# STM32G473xx register map
File version: 1.0
Registers are 32-bit, read-write, reset 0x0 unless marked. A register's access mark holds for its fields unless they carry their own. Offsets are from the block's base; [hi:lo] are bit positions; {n}, {i} and the like mark numbered series.

## OPAMP — Operational Amplifier (OPAMP)
Base 0x40010300
Same registers: OPAMP1 0x40010300 (alternate view of OPAMP), OPAMP2 0x40010304, OPAMP3 0x40010308, OPAMP4 0x4001030C, OPAMP5 0x40010310, OPAMP6 0x40010314
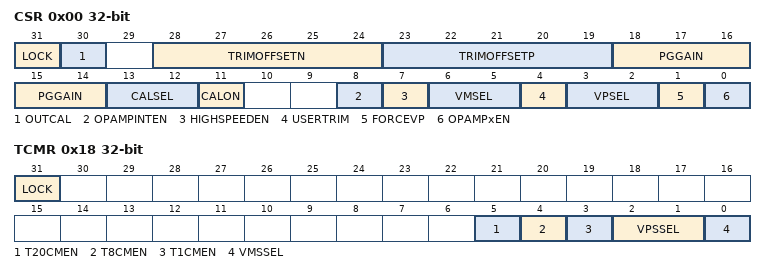
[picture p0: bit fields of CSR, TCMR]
0x00 CSR — OPAMP control/status register
  [31] LOCK — OPAMP control/status register lock
  [30] OUTCAL — OPAMP output status flag
  [28:24] TRIMOFFSETN — Offset trimming value (NMOS)
  [23:19] TRIMOFFSETP — Offset trimming value (PMOS)
  [18:14] PGGAIN — Gain in PGA mode
  [13:12] CALSEL — Calibration selection
  [11] CALON — Calibration mode enable
    0=FUNCTIONAL (OPAMP functional mode); 1=CALIBRATION (OPAMP calibration mode)
  [8] OPAMPINTEN — Internal output enable
    0=DISABLED (OPAMP internal output to ADC disabled.); 1=ENABLED
  [7] HIGHSPEEDEN — High speed mode enable
    0=NORMALSPEED (OPAMP output in normal mode); 1=HIGHSPEED (OPAMP output in highspeed mode)
  [6:5] VMSEL — Inverting input selection
    0=IO0; 1=IO1; 2=CONNECT_NO
  [4] USERTRIM — User trimming enable
    0=FACTORY (OPAMP trimming factors set to factory values); 1=USER (OPAMP trimming factors set to user values)
  [3:2] VPSEL — Non inverting input selection
    {v}=IO{v} (v=0..3)
  [1] FORCEVP — Connect the internal references to the plus input of the OPAMPX
  [0] OPAMPxEN — OPAMP enable
0x18 TCMR — OPAMP timer controlled mux mode register
  [31] LOCK — OPAMP SW control register lock
  [5] T20CMEN — Timer 20 controlled mux mode enable
  [4] T8CMEN — Timer 8 controlled mux mode enable
  [3] T1CMEN — Timer 1 controlled mux mode enable
  [2:1] VPSSEL — Secondary non inverting input selection
    {v}=IO{v}_SEC (v=0..3)
  [0] VMSSEL — Secondary inverting input selection
    0=IO0_SEC; 1=IO1_SEC

## EXTI — External Interrupt/Event Controller
Base 0x40010400
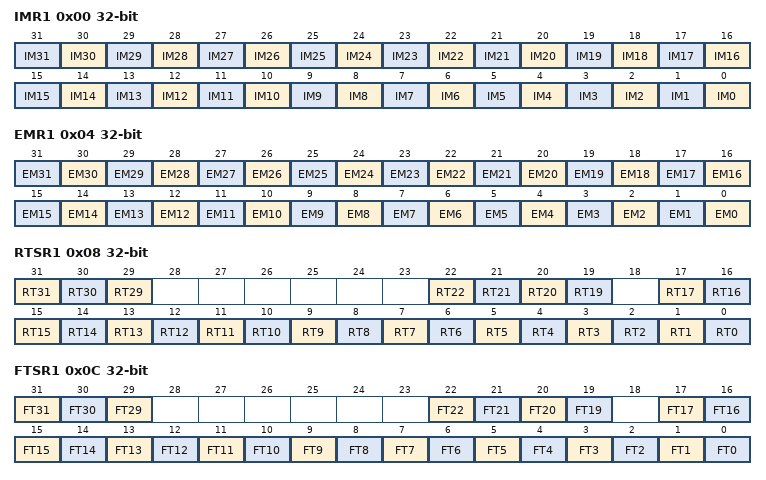
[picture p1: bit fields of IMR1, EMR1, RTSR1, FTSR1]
0x00 IMR1 — EXTI Interrupt mask register 1
  [n] IM{n} (n=0..31) — Interrupt Mask on line {n}
0x04 EMR1 — EXTI Event mask register 1
  [n] EM{n} (n=0..31) — Event Mask on line {n}
0x08 RTSR1 — EXTI Rising trigger selection register 1
  [31] RT31 — Rising trigger event configuration bit of line 31
  [30] RT30 — Rising trigger event configuration bit of line 30
  [29] RT29 — Rising trigger event configuration bit of line 29
  [n] RT{n} (n=19..22) — Rising trigger event configuration bit of line {n}
  [n] RT{n} (n=0..17) — Rising trigger event configuration bit of line {n}
0x0C FTSR1 — EXTI Falling trigger selection register 1
  [31] FT31 — Falling trigger event configuration bit of line 31
  [30] FT30 — Falling trigger event configuration bit of line 30
  [29] FT29 — Falling trigger event configuration bit of line 29
  [n] FT{n} (n=19..22) — Falling trigger event configuration bit of line {n}
  [n] FT{n} (n=0..17) — Falling trigger event configuration bit of line {n}
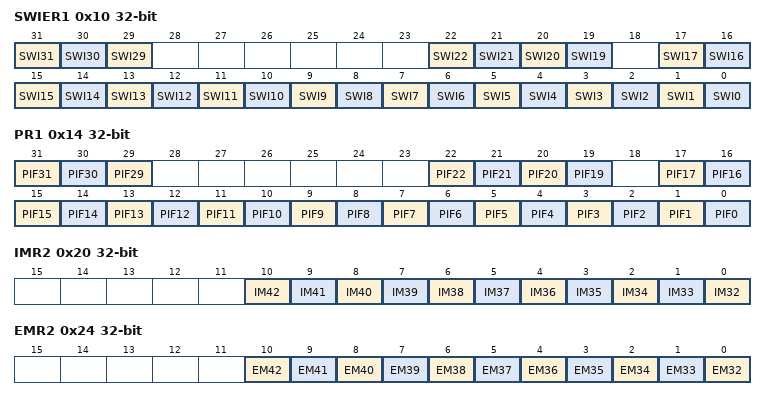
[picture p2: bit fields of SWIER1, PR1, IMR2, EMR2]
0x10 SWIER1 — EXTI Software interrupt event register 1
  [31] SWI31 — Software Interrupt on line 31
  [30] SWI30 — Software Interrupt on line 30
  [29] SWI29 — Software Interrupt on line 29
  [n] SWI{n} (n=19..22) — Software Interrupt on line {n}
  [n] SWI{n} (n=0..17) — Software Interrupt on line {n}
0x14 PR1 — EXTI Pending register 1
  [31] PIF31 — Pending bit for line 31
  [30] PIF30 — Pending bit for line 30
  [29] PIF29 — Pending bit for line 29
  [n] PIF{n} (n=19..22) — Pending bit for line {n}
  [n] PIF{n} (n=0..17) — Pending bit for line {n}
0x20 IMR2 — EXTI Interrupt mask register 2
  [n-32] IM{n} (n=32..42) — Interrupt Mask on line {n}
0x24 EMR2 — EXTI Event mask register 2
  [n-32] EM{n} (n=32..42) — Event Mask on line {n}
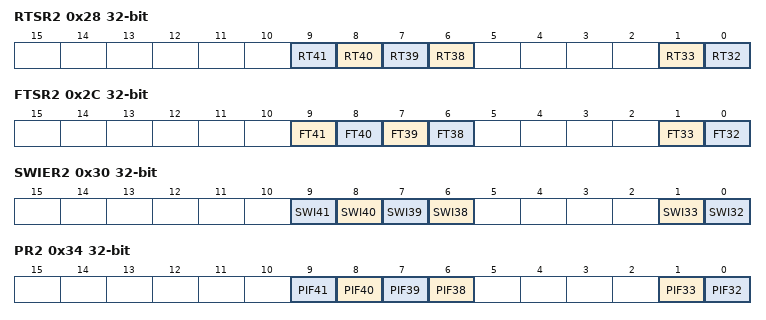
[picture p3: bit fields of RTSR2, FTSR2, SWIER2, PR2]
0x28 RTSR2 — EXTI Rising trigger selection register 2
  [n-32] RT{n} (n=38..41) — Rising trigger event configuration bit of line {n}
  [1] RT33 — Rising trigger event configuration bit of line 33
  [0] RT32 — Rising trigger event configuration bit of line 32
0x2C FTSR2 — EXTI Falling trigger selection register 2
  [9] FT41 — Falling trigger event configuration bit of line 41
  [8] FT40 — Falling trigger event configuration bit of line 40
  [7] FT39 — Falling trigger event configuration bit of line 39
  [6] FT38 — Falling trigger event configuration bit of line 37
  [1] FT33 — Falling trigger event configuration bit of line 33
  [0] FT32 — Falling trigger event configuration bit of line 32
0x30 SWIER2 — EXTI Software interrupt event register 2
  [n-32] SWI{n} (n=38..41) — Software Interrupt on line {n}
  [1] SWI33 — Software Interrupt on line 33
  [0] SWI32 — Software Interrupt on line 32
0x34 PR2 — EXTI Pending register 2
  [n-32] PIF{n} (n=38..41) — Pending bit for line {n}
  [1] PIF33 — Pending bit for line 33
  [0] PIF32 — Pending bit for line 32
